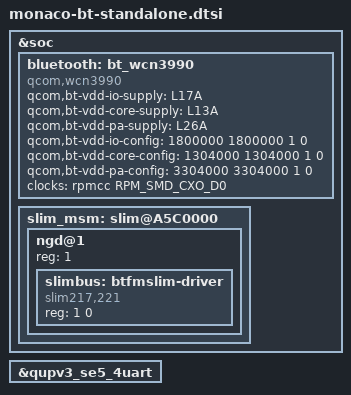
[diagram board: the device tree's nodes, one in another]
#include <dt-bindings/interconnect/qcom,monaco.h>
#include <dt-bindings/soc/qcom,ipcc.h>
#include <dt-bindings/clock/qcom,rpmcc.h>
#include <dt-bindings/mfd/qcom-rpm.h>

&soc {
	bluetooth: bt_wcn3990 {
		compatible = "qcom,wcn3990";
		//qcom,bt-sw-ctrl-gpio = <&tlmm 69 GPIO_ACTIVE_HIGH>;
		qcom,bt-vdd-io-supply = <&L17A>;  /* IO */
		qcom,bt-vdd-core-supply = <&L13A>; /* RFA */
		qcom,bt-vdd-pa-supply = <&L26A>; /* CH0 */

		qcom,bt-vdd-io-config = <1800000 1800000 1 0>;
		qcom,bt-vdd-core-config = <1304000 1304000 1 0>;
		qcom,bt-vdd-pa-config = <3304000 3304000 1 0>;
		clocks = <&rpmcc RPM_SMD_CXO_D0>;
		clock-names = "cx0_do";
		status = "ok";
	};
	slim_msm: slim@A5C0000 {
		status =  "ok";
		ngd@1 {
			reg = <1>;
			#address-cells = <1>;
			#size-cells = <1>;
			//slimbus child nodes
			slimbus: btfmslim-driver {
					compatible = "slim217,221";
					reg = <1 0>;
			};
		};
	};
};

&qupv3_se5_4uart {
	status = "ok";
};

